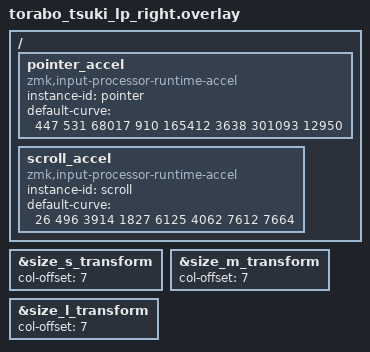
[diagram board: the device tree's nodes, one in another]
#include "torabo_tsuki_lp.dtsi"
#include <input/processors.dtsi>
#include <dt-bindings/zmk/input_transform.h>

/ {
    // Runtime-editable speed curves. The Web editor exposes these as
    // the "pointer" and "scroll" instances.
    pointer_accel: pointer_accel {
        compatible = "zmk,input-processor-runtime-accel";
        #input-processor-cells = <0>;
        instance-id = "pointer";
        default-curve = <447 531 68017 910 165412 3638 301093 12950>;
    };

    scroll_accel: scroll_accel {
        compatible = "zmk,input-processor-runtime-accel";
        #input-processor-cells = <0>;
        instance-id = "scroll";
        default-curve = <26 496 3914 1827 6125 4062 7612 7664>;
    };
};

&size_s_transform {
    col-offset = <7>;
};

&size_m_transform {
    col-offset = <7>;
};

&size_l_transform {
    col-offset = <7>;
};
